VERSION ""

NS_ :

BS_:

BU_: Controller Plant Orchestrator Vector__XXX

BO_ 256 Setpoint_Cmd: 8 Orchestrator
 SG_ Setpoint : 0|32@1- (0.001,0) [-2147483.648|2147483.647] "" Vector__XXX

BO_ 257 Measurement_Fb: 8 Plant
 SG_ Measurement : 0|32@1- (0.001,0) [-2147483.648|2147483.647] "" Vector__XXX

BO_ 258 Control_Output: 8 Controller
 SG_ ControlOutput : 0|32@1- (0.001,0) [-2147483.648|2147483.647] "" Vector__XXX

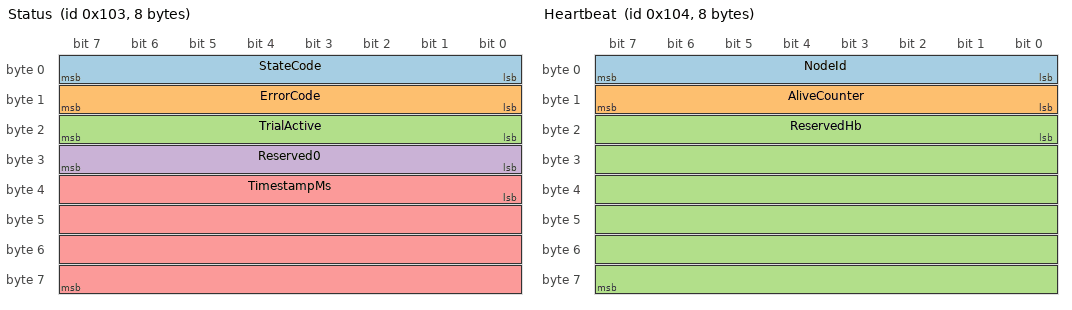
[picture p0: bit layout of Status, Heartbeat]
BO_ 259 Status: 8 Controller
 SG_ StateCode : 0|8@1+ (1,0) [0|255] "" Vector__XXX
 SG_ ErrorCode : 8|8@1+ (1,0) [0|255] "" Vector__XXX
 SG_ TrialActive : 16|8@1+ (1,0) [0|1] "" Vector__XXX
 SG_ Reserved0 : 24|8@1+ (1,0) [0|255] "" Vector__XXX
 SG_ TimestampMs : 32|32@1+ (1,0) [0|4294967295] "ms" Vector__XXX

BO_ 260 Heartbeat: 8 Controller
 SG_ NodeId : 0|8@1+ (1,0) [0|255] "" Vector__XXX
 SG_ AliveCounter : 8|8@1+ (1,0) [0|255] "" Vector__XXX
 SG_ ReservedHb : 16|48@1+ (1,0) [0|281474976710655] "" Vector__XXX
